# CH585SFR register map
Vendor: WCH Ltd.; Series: CH58x; File version: 1.0
CPU: RISC-V r0p0, little endian, no MPU, no FPU, 2 interrupt priority bits
Registers are 8-bit, Read or Write, reset 0x0 unless marked. A register's access mark holds for its fields unless they carry their own. Offsets are from the block's base; [hi:lo] are bit positions.

## System_control — System control related registers
Base 0x40001000
0x40 R8_SAFE_ACCESS_SIG read or write reset not defined — WO, safe accessing sign register, must write SAFE_ACCESS_SIG1 then SAFE_ACCESS_SIG2 to enter safe accessing mode
  [6:4] RB_SAFE_ACC_TIMER ro — RO, safe accessing timer bit mask (16*clock number)
  [3] RB_SAFE_ACC_ACT ro — RO, indicate safe accessing status now: 0=locked, read only, 1=safe/unlocked (SAM), write enabled
  [2] RB_CHIP_ID0 ro — RO, Chip identification code
  [1:0] RB_SAFE_ACC_MODE ro — RO, current safe accessing mode: 11=safe unlocked (SAM), other=locked (00..01..10..11)
  [7:0] R8_SAFE_ACCESS_SIG wo — WO, safe accessing sign register, must write 0x57 then 0xA8 to enter safe accessing mode
0x41 R8_CHIP_ID Read only for Fixed value reset not defined — RF, chip ID register, always is ID_CH59*
  [7:0] R8_CHIP_ID ro — RF,chip ID register
0x42 R8_SAFE_ACCESS_ID Read only for Fixed value reset 0xC — RF, safe accessing ID register, always 0x0C
  [7:0] R8_SAFE_ACCESS_ID ro — RF,safe accessing ID register
0x43 R8_WDOG_COUNT — RW, watch-dog count, count by clock frequency Fsys/131072
  [7:0] R8_WDOG_COUNT — RW,watch-dog count, count by clock frequency Fsys/131072
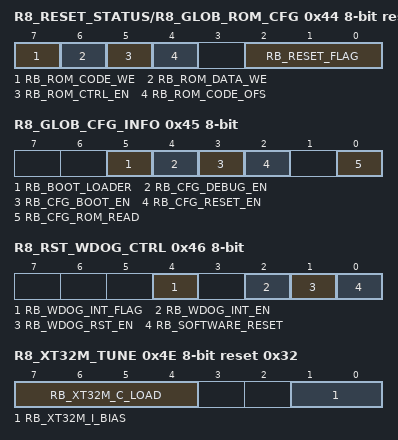
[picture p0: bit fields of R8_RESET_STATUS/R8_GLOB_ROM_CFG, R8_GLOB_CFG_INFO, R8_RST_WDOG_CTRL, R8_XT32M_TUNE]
0x44 R8_RESET_STATUS/R8_GLOB_ROM_CFG Read only reset 0x1 — RWA, reset status, SAM or flash ROM configuration
  [7] RB_ROM_CODE_WE Read or Write under safe Accessing mode — RWA, enable flash ROM code area being erase or write
  [6] RB_ROM_DATA_WE Read or Write under safe Accessing mode — RWA,enable flash ROM data and code area being erase/write
  [5] RB_ROM_CTRL_EN Read or Write under safe Accessing mode — RWA, enable flash ROM control interface enable
  [4] RB_ROM_CODE_OFS Read or Write under safe Accessing mode — RWA, code offset address selection in Flash ROM: 0=start address 0x000000, 1=start address 0x008000
  [2:0] RB_RESET_FLAG ro — RO, recent reset flag
0x45 R8_GLOB_CFG_INFO ro reset not defined — RO, global configuration information and status
  [5] RB_BOOT_LOADER — RO, indicate boot loader status: 0=application status (by software reset), 1=boot loader status
  [4] RB_CFG_DEBUG_EN — RO, debug enable status
  [3] RB_CFG_BOOT_EN — RO, boot-loader enable status
  [2] RB_CFG_RESET_EN — RO, manual reset input enable status
  [0] RB_CFG_ROM_READ — RO, indicate protected status of Flash ROM code and data: 0=reading protect, 1=enable read by external programmer
0x46 R8_RST_WDOG_CTRL Read or Write under safe Accessing mode — RWA, reset and watch-dog control, SAM
  [4] RB_WDOG_INT_FLAG — RW1, watch-dog timer overflow interrupt flag, cleared by RW1 or reload watch-dog count or __SEV(Send-Event)
  [2] RB_WDOG_INT_EN — RWA, watch-dog timer overflow interrupt enable: 0=disable, 1=enable
  [1] RB_WDOG_RST_EN — RWA, enable watch-dog reset if watch-dog timer overflow: 0=as timer only, 1=enable reset if timer overflow
  [0] RB_SOFTWARE_RESET — WA or WZ, global software reset, high action, auto clear
0x47 R8_GLOB_RESET_KEEP — RW, value keeper during global reset
0x4B R8_PLL_CONFIG Read or Write under safe Accessing mode reset 0xA — RWA, PLL configuration control, SAM
  [5:0] RB_PLL_CFG_DAT Read or Write — RWA, PLL configure data
0x4E R8_XT32M_TUNE Read or Write under safe Accessing mode reset 0x32 — RWA, external 32MHz oscillator tune control, SAM
  [7:4] RB_XT32M_C_LOAD — RWA, external 32MHz oscillator load capacitor tune: Cap = RB_XT32M_C_LOAD * 2 + 10pF
  [1:0] RB_XT32M_I_BIAS — RWA, external 32MHz oscillator bias current tune: 00=75% current, 01=standard current, 10=125% current, 11=150% current
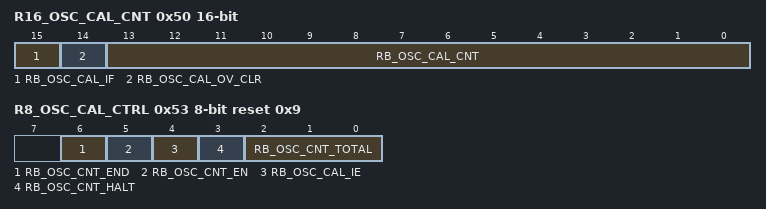
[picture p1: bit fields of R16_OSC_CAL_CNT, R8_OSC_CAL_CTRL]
0x50 R16_OSC_CAL_CNT 16-bit ro reset not defined — RO, system clock count value for 32KHz multi-cycles
  [15] RB_OSC_CAL_IF — RW1, interrupt flag for oscillator capture end, set 1 to clear
  [14] RB_OSC_CAL_OV_CLR — RW1, indicate R8_OSC_CAL_OV_CNT not zero, set 1 to clear R8_OSC_CAL_OV_CNT
  [13:0] RB_OSC_CAL_CNT — RO, system clock count value for 32KHz multi-cycles
0x52 R8_OSC_CAL_OV_CNT Read Only — RO, oscillator frequency calibration overflow times
0x53 R8_OSC_CAL_CTRL Read or Write under safe Accessing mode reset 0x9 — RWA, oscillator frequency calibration control, SAM
  [6] RB_OSC_CNT_END — RWA, select oscillator capture end mode: 0=normal, 1=append 2 cycles
  [5] RB_OSC_CNT_EN — RWA, calibration counter enable
  [4] RB_OSC_CAL_IE — RWA, interrupt enable for oscillator capture end
  [3] RB_OSC_CNT_HALT ro — RO, calibration counter halt status: 0=counting, 1=halt for reading count value
  [2:0] RB_OSC_CNT_TOTAL — RWA, total cycles mode for oscillator capture
